# PIC32CK0512SG00100 register map
Vendor: Microchip Technology; Series: PIC32CKSG00; File version: 0
CPU: CM33 r0p0, little endian, MPU, FPU, DSP, 3 interrupt priority bits, 158 interrupts, 23 SAU regions
Registers are 32-bit, read-write, reset 0x0 unless marked. A register's access mark holds for its fields unless they carry their own. Offsets are from the block's base; [hi:lo] are bit positions; lines under a group give offsets from that group; {n}, {i} and the like mark numbered series.

## CoreDebug — Debug Control Block
Base 0xE000EDF0
Same registers: CoreDebug_NS 0xE002EDF0
0x00 DHCSR — Debug Halting Control and Status Register
  [26] S_RESTART_ST ro — Restart sticky status
  [25] S_RESET_ST ro — Reset sticky status
  [24] S_RETIRE_ST ro — Retire sticky status
  [23] S_FPD ro — Floating-point registers Debuggable
  [22] S_SUIDE ro — Secure unprivileged-only halting debug enabled
  [21] S_NSUIDE ro — Non-secure unprivileged-only haltingdebug enabled
  [20] S_SDE ro — Secure debug enabled
  [19] S_LOCKUP ro — Lockup status
  [18] S_SLEEP ro — Sleeping status
  [17] S_HALT ro — Halted status
  [16] S_REGRDY ro — Register ready status
  [31:16] DBGKEY wo — Debug key, must write 0xA05F to enable writes
  [6] C_PMOV — Halt on PMU overflow contro
  [5] C_SNAPSTALL — Snap stall control
  [3] C_MASKINTS — Mask PendSV, SysTick and external configurable interrupts
  [2] C_STEP — Enable single step
  [1] C_HALT — Halt processor
  [0] C_DEBUGEN — Enable Halting debug
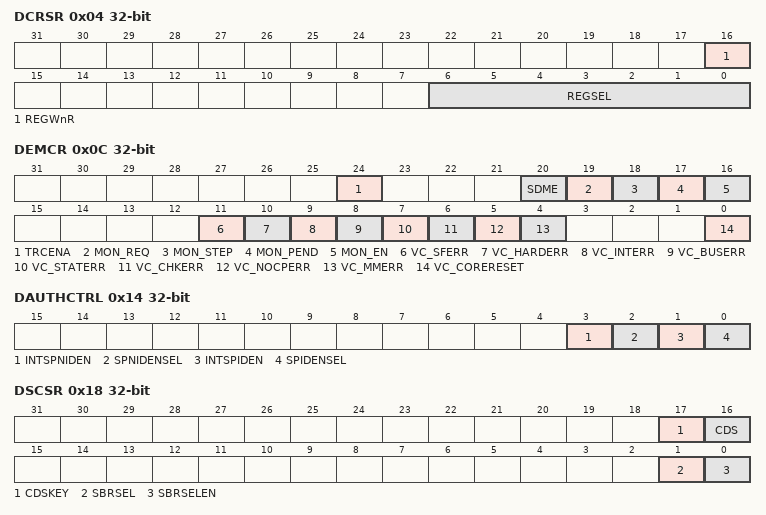
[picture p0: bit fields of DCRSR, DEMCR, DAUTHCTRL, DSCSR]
0x04 DCRSR wo — Debug Core Register Select Register
  [16] REGWnR — Register write/not-read access
  [6:0] REGSEL — Register selector
0x08 DCRDR — Debug Core Register Data Register
  [31:0] DBGTMP — Data temporary buffer
0x0C DEMCR — Debug Exception and Monitor Control Register
  [24] TRCENA — Global DWT and ITM features enable
  [20] SDME — Secure DebugMonitor enable
  [19] MON_REQ — DebugMonitor semaphore bit
  [18] MON_STEP — Enable DebugMonitor stepping
  [17] MON_PEND — DebugMonitor pending state
  [16] MON_EN — DebugMonitor enable
  [11] VC_SFERR — SecureFault exception Halting debug vector catch enable
  [10] VC_HARDERR — HardFault exception Halting debug vector catch enable
  [9] VC_INTERR — Exception entry and return faults Halting debug vector catch enable
  [8] VC_BUSERR — BusFault exception Halting debug vector catch enable
  [7] VC_STATERR — UsageFault exception state information error Halting debug vector catch enable
  [6] VC_CHKERR — UsageFault exception checking error Halting debug vector catch enable
  [5] VC_NOCPERR — UsageFault exception coprocessor access Halting debug vector catch enable
  [4] VC_MMERR — MemManage exception Halting debug vector catch enable
  [0] VC_CORERESET — Core reset Halting debug vector catch enable
0x14 DAUTHCTRL — Debug Authentication Control Register
  [3] INTSPNIDEN — Internal Secure non-invasive debug enable
  [2] SPNIDENSEL — Secure non-invasive debug enable select
  [1] INTSPIDEN — Internal Secure invasive debug enable
  [0] SPIDENSEL — Secure invasive debug enable select
0x18 DSCSR — Debug Security Control and Status Register
  [17] CDSKEY — CDS field write-enable key
  [16] CDS — Current domain Secure
  [1] SBRSEL — Secure Banked register select
  [0] SBRSELEN — Secure Banked register select enable

## EBI — External Bus Interface
Base 0x4502C000
{0x0+0x10*i} CS_X[{i}] (i=0..3) group
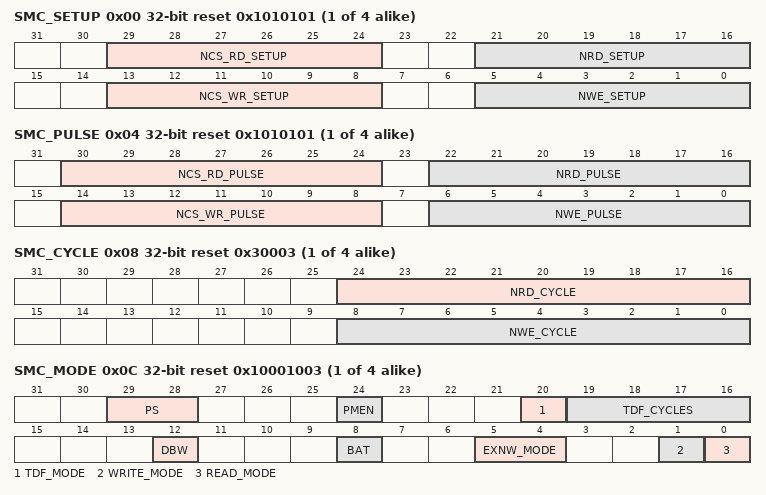
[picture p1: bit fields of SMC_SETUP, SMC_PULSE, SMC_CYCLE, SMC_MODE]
  0x00 SMC_SETUP reset 0x1010101
    [29:24] NCS_RD_SETUP — NCS Setup Length in READ Access
    [21:16] NRD_SETUP — NRD Setup Length
    [13:8] NCS_WR_SETUP — NCS Setup Length in WRITE Access
    [5:0] NWE_SETUP — NWE Setup Length
  0x04 SMC_PULSE reset 0x1010101
    [30:24] NCS_RD_PULSE — NCS Pulse Length in READ Access
    [22:16] NRD_PULSE — NRD Pulse Length
    [14:8] NCS_WR_PULSE — NCS Pulse Length in WRITE Access
    [6:0] NWE_PULSE — NWE Pulse Length
  0x08 SMC_CYCLE reset 0x30003
    [24:16] NRD_CYCLE — Total Read Cycle Length
    [8:0] NWE_CYCLE — Total Write Cycle Length
  0x0C SMC_MODE reset 0x10001003
    [29:28] PS — Page Size
      0=_4_BYTE (4-byte page); 1=_8_BYTE (8-byte page); 2=_16_BYTE (16-byte page); 3=_32_BYTE (32-byte page)
    [24] PMEN — Page Mode Enabled
    [20] TDF_MODE — TDF Optimization
    [19:16] TDF_CYCLES — Data Float Time
    [12] DBW — Data Bus Width
      0=_8_BIT (8-bit Data Bus); 1=_16_BIT (16-bit Data Bus)
    [8] BAT — Byte Access Type
      0=BYTE_SELECT (Byte select access type:- Write operation is controlled using NCS, NWE, NBS0, NBS1.- Read operation is controlled using NCS, NRD, NBS0, NBS1.); 1=BYTE_WRITE (Byte write access type:- Write operation is controlled using NCS, NWR0, NWR1.- Read operation is controlled using NCS and NRD.)
    [5:4] EXNW_MODE — NWAIT Mode
      0=DISABLED (Disabled-The NWAIT input signal is ignored on the corresponding chip select.); 2=FROZEN (Frozen Mode-If asserted, the NWAIT signal freezes the current read or write cycle. After deassertion, the read/write cycle is resumed from the point where it was stopped.); 3=READY (Ready Mode-The NWAIT signal indicates the availability of the external device at the end of the pulse of the controlling read or write signal, to complete the access. If high, the access normally completes. If low, the access is extended until NWAIT returns high.)
    [1] WRITE_MODE
    [0] READ_MODE
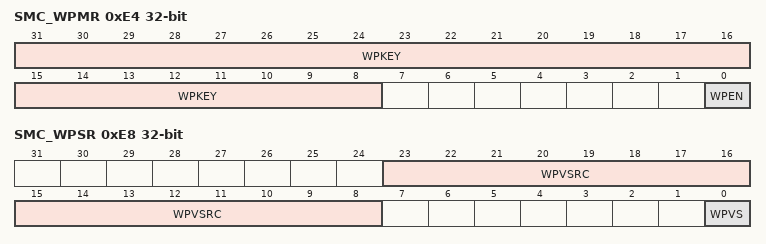
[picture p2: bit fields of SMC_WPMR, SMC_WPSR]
0xE4 SMC_WPMR — SMC Write Protection Mode Register
  [31:8] WPKEY — Write Protection Key
    0x534D43=PASSWD (Writing any other value in this field aborts the write operation of the WPEN bit. Always reads as 0.)
  [0] WPEN — Write Protect Enable
0xE8 SMC_WPSR ro — SMC Write Protection Status Register
  [23:8] WPVSRC — Write Protection Violation Source
  [0] WPVS — Write Protection Violation Status

## Notices in the file
Copyright (c) 2026 Microchip Technology Inc.
SPDX-License-Identifier: Apache-2.0
Licensed under the Apache License, Version 2.0 (the "License");
you may not use this file except in compliance with the License.
You may obtain a copy of the License at
http://www.apache.org/licenses/LICENSE-2.0
Unless required by applicable law or agreed to in writing, software
distributed under the License is distributed on an "AS IS" BASIS,
WITHOUT WARRANTIES OR CONDITIONS OF ANY KIND, either express or implied.
See the License for the specific language governing permissions and
limitations under the License.
